# STM32U5G9xx register map
File version: 1.0
Registers are 32-bit, read-write, reset 0x0 unless marked. A register's access mark holds for its fields unless they carry their own. Offsets are from the block's base; [hi:lo] are bit positions; 'fields as' and 'values as' point back to an identical list.

## COMP12 — Comparator
Base 0x46005400
Same registers: COMP12_S 0x56005400
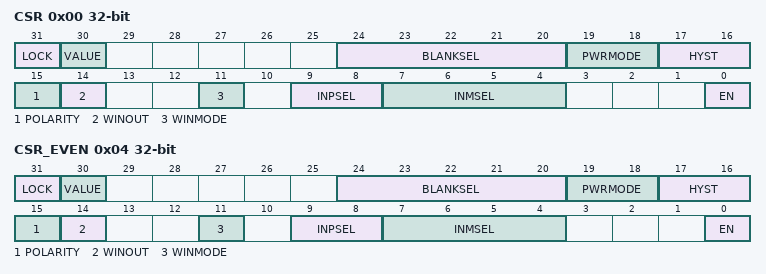
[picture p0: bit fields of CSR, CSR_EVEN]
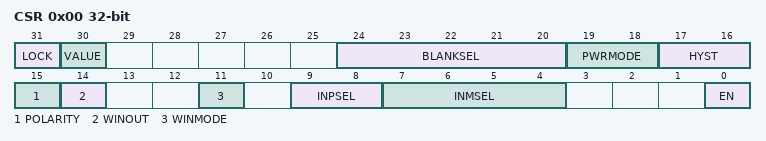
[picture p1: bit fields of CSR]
0x00 CSR — Comparator control and status register
  [31] LOCK — Comparator lock
  [30] VALUE — Comparator output level
  [24:20] BLANKSEL — Comparator blanking source
    0=NONE (Comparator output without blanking); 1=TIM1_OC5 (Comparator output blanking source TIM1 OC5 for COMP1 Instance); 2=TIM2_OC3 (Comparator output blanking source TIM2 OC3 for COMP1 Instance); 4=TIM3_OC3 (Comparator output blanking source TIM3 OC3 for COMP1 Instance)
  [19:18] PWRMODE — Comparator power mode
    0=HIGHSPEED (COMP power mode to high speed); 1=MEDIUMSPEED (COMP power mode to medium speed); 3=ULTRALOWPOWER (COMP power mode to ultra-low power)
  [17:16] HYST — Comparator input hysteresis
    0=NONE (No hysteresis); 1=LOW (Hysteresis level low); 2=MEDIUM (Hysteresis level medium); 3=HIGH (Hysteresis level high)
  [15] POLARITY — Comparator output polarity
    0=NONINVERTED (COMP output polarity is not inverted: comparator output is high when the plus (non-inverting) input is at a higher voltage than the minus (inverting) input); 1=INVERTED (COMP output polarity is inverted: comparator output is low when the plus (non-inverting) input is at a lower voltage than the minus (inverting) input)
  [14] WINOUT — Pair of comparators window output level. Bit intended to be used with COMP common instance (COMP_Common_TypeDef)
  [11] WINMODE — Pair of comparators window mode. Bit intended to be used with COMP common instance (COMP_Common_TypeDef)
  [9:8] INPSEL — Comparator input plus selection
    0=IO1 (Comparator input plus connected to IO1 (pin PC5 for COMP1, pin PB4 for COMP2)); 1=IO2 (Comparator input plus connected to IO2 (pin PB2 for COMP1, pin PB6 for COMP2)); 2=IO3 (Comparator input plus connected to IO3 (pin PA2 for COMP1))
  [7:4] INMSEL — Comparator input minus selection
    0=MINUS_1_4VREFINT (Comparator input minus connected to 1/4 VrefInt); 1=MINUS_1_2VREFINT (Comparator input minus connected to 1/2 VrefInt); 2=MINUS_3_4VREFINT (Comparator input minus connected to 3/4 VrefInt); 3=VREFINT (Comparator input minus connected to VrefInt); 4=DAC1_CH1 (Comparator input minus connected to DAC1 channel 1 (DAC_OUT1)); 5=DAC1_CH2 (Comparator input minus connected to DAC1 channel 2 (DAC_OUT2)); 6=IO1 (Comparator input minus connected to IO1 (pin PB1 for COMP1, pin PB3 for COMP2)); 7=IO2 (Comparator input minus connected to IO2 (pin PC4 for COMP1, pin PB7 for COMP2))
  [0] EN — Comparator enable
0x04 CSR_EVEN — COMP control and status register located in register of comparator instance even, used for bits common to several COMP instances
  fields as CSR

## COMP1 — Comparator
Base 0x46005400; alternate view of COMP12
Same registers: COMP2 0x46005404, COMP1_S 0x56005400 (alternate view of COMP12_S), COMP2_S 0x56005404
0x00 CSR — Comparator control and status register
  [31] LOCK — Comparator lock
  [30] VALUE — Comparator output level
  [24:20] BLANKSEL — Comparator blanking source
    0=NONE (Comparator output without blanking); 1=TIM1_OC5 (Comparator output blanking source TIM1 OC5 for COMP1 Instance); 2=TIM2_OC3 (Comparator output blanking source TIM2 OC3 for COMP1 Instance); 4=TIM3_OC3 (Comparator output blanking source TIM3 OC3 for COMP1 Instance)
  [19:18] PWRMODE — Comparator power mode
    0=HIGHSPEED (COMP power mode to high speed); 1=MEDIUMSPEED (COMP power mode to medium speed); 3=ULTRALOWPOWER (COMP power mode to ultra-low power)
  [17:16] HYST — Comparator input hysteresis
    0=NONE (No hysteresis); 1=LOW (Hysteresis level low); 2=MEDIUM (Hysteresis level medium); 3=HIGH (Hysteresis level high)
  [15] POLARITY — Comparator output polarity
    0=NONINVERTED (COMP output polarity is not inverted: comparator output is high when the plus (non-inverting) input is at a higher voltage than the minus (inverting) input); 1=INVERTED (COMP output polarity is inverted: comparator output is low when the plus (non-inverting) input is at a lower voltage than the minus (inverting) input)
  [14] WINOUT — Pair of comparators window output level. Bit intended to be used with COMP common instance (COMP_Common_TypeDef)
  [11] WINMODE — Pair of comparators window mode. Bit intended to be used with COMP common instance (COMP_Common_TypeDef)
  [9:8] INPSEL — Comparator input plus selection
    0=IO1 (Comparator input plus connected to IO1 (pin PC5 for COMP1, pin PB4 for COMP2)); 1=IO2 (Comparator input plus connected to IO2 (pin PB2 for COMP1, pin PB6 for COMP2)); 2=IO3 (Comparator input plus connected to IO3 (pin PA2 for COMP1))
  [7:4] INMSEL — Comparator input minus selection
    0=MINUS_1_4VREFINT (Comparator input minus connected to 1/4 VrefInt); 1=MINUS_1_2VREFINT (Comparator input minus connected to 1/2 VrefInt); 2=MINUS_3_4VREFINT (Comparator input minus connected to 3/4 VrefInt); 3=VREFINT (Comparator input minus connected to VrefInt); 4=DAC1_CH1 (Comparator input minus connected to DAC1 channel 1 (DAC_OUT1)); 5=DAC1_CH2 (Comparator input minus connected to DAC1 channel 2 (DAC_OUT2)); 6=IO1 (Comparator input minus connected to IO1 (pin PB1 for COMP1, pin PB3 for COMP2)); 7=IO2 (Comparator input minus connected to IO2 (pin PC4 for COMP1, pin PB7 for COMP2))
  [0] EN — Comparator enable
